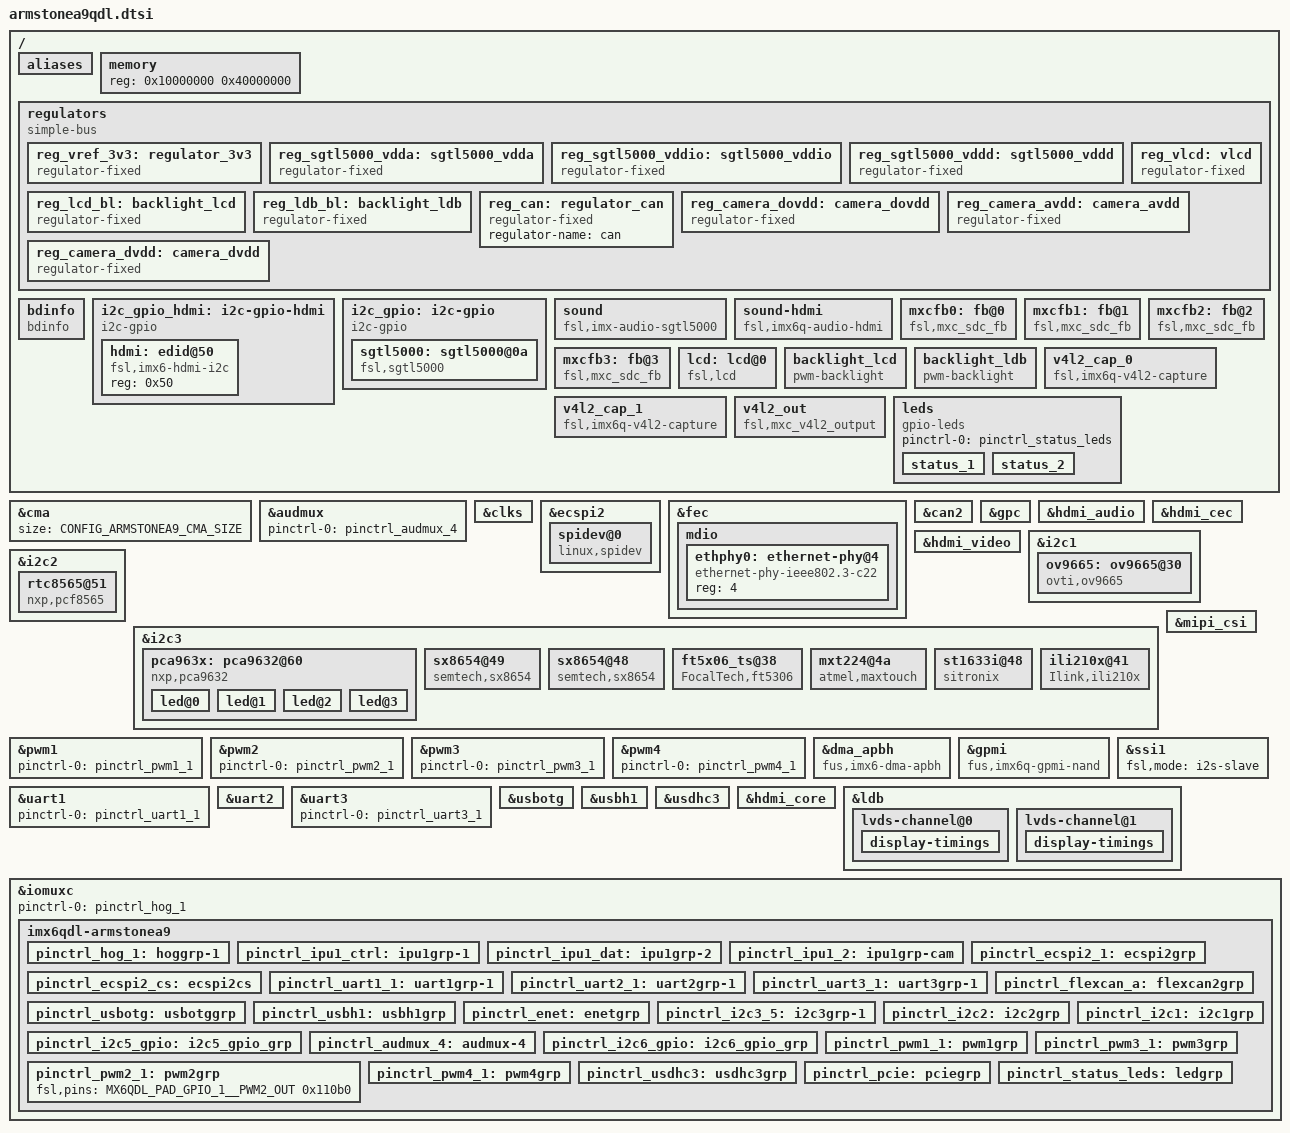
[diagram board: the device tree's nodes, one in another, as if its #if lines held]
/*
 * Copyright 2016 F&S Elektronik Systeme GmbH
 *
 * This program is free software; you can redistribute it and/or modify
 * it under the terms of the GNU General Public License version 2 as
 * published by the Free Software Foundation.
 */

#include <dt-bindings/pwm/pwm.h>

/*
 * When using one IPU, having LCD and LVDS0 at the same time is not possible,
 * because both devices would need to use display 0. But this can be simulated
 * by using LVDS1 instead of LVDS0 and activating Dual Mode.
 */
#ifdef CONFIG_ARMSTONEA9_USE_ONE_IPU
#undef CONFIG_ARMSTONEA9_MXCFB2
#undef CONFIG_ARMSTONEA9_MXCFB3

#if ((CONFIG_ARMSTONEA9_MXCFB0 == DISPLAY_LCD) \
	&& (CONFIG_ARMSTONEA9_MXCFB1 == DISPLAY_LVDS0))
#undef CONFIG_ARMSTONEA9_MXCFB1
#define CONFIG_ARMSTONEA9_MXCFB1		DISPLAY_LVDS1
#define __MOVE_LVDS0_TO_LVDS1_DUAL_MODE__
#endif

#if ((CONFIG_ARMSTONEA9_MXCFB0 == DISPLAY_LVDS0) \
	&& (CONFIG_ARMSTONEA9_MXCFB1 == DISPLAY_LCD))
#undef CONFIG_ARMSTONEA9_MXCFB0
#define CONFIG_ARMSTONEA9_MXCFB0		DISPLAY_LVDS1
#define __MOVE_LVDS0_TO_LVDS1_DUAL_MODE__
#endif

#ifdef __MOVE_LVDS0_TO_LVDS1_DUAL_MODE__
#undef CONFIG_ARMSTONEA9_LVDS1_MAPPING
#undef CONFIG_ARMSTONEA9_LVDS1_BPP
#undef CONFIG_ARMSTONEA9_LVDS1_PIX_FMT
#undef CONFIG_ARMSTONEA9_LVDS1_DATA_WIDTH
#undef CONFIG_ARMSTONEA9_LVDS1_TIMING
#define CONFIG_ARMSTONEA9_LVDS1_MAPPING		CONFIG_ARMSTONEA9_LVDS0_MAPPING
#define CONFIG_ARMSTONEA9_LVDS1_BPP		CONFIG_ARMSTONEA9_LVDS0_BPP
#define CONFIG_ARMSTONEA9_LVDS1_PIX_FMT		CONFIG_ARMSTONEA9_LVDS0_PIX_FMT
#define CONFIG_ARMSTONEA9_LVDS1_DATA_WIDTH	CONFIG_ARMSTONEA9_LVDS0_DATA_WIDTH
#define CONFIG_ARMSTONEA9_LVDS1_TIMING		CONFIG_ARMSTONEA9_LVDS0_TIMING
#ifndef CONFIG_ARMSTONEA9_LVDS_DUAL_MODE
#define CONFIG_ARMSTONEA9_LVDS_DUAL_MODE
#endif
#endif
#endif /* CONFIG_ARMSTONEA9_USE_ONE_IPU */

/* Do we have LCD? */
#if ((CONFIG_ARMSTONEA9_MXCFB0 == DISPLAY_LCD) \
    || (CONFIG_ARMSTONEA9_MXCFB1 == DISPLAY_LCD) \
    || (CONFIG_ARMSTONEA9_MXCFB2 == DISPLAY_LCD) \
    || (CONFIG_ARMSTONEA9_MXCFB3 == DISPLAY_LCD))
#define CONFIG_ARMSTONEA9_LCD
#if ((CONFIG_ARMSTONEA9_MXCFB0 == DISPLAY_LCD) \
    || (CONFIG_ARMSTONEA9_MXCFB1 == DISPLAY_LCD))
#define __LCD_ON_0_OR_1__	1
#define __LCD_ON_2_OR_3__	0
#else
#define __LCD_ON_0_OR_1__	0
#define __LCD_ON_2_OR_3__	1
#endif
#endif

/* Do we have HDMI? */
#if ((CONFIG_ARMSTONEA9_MXCFB0 == DISPLAY_HDMI) \
    || (CONFIG_ARMSTONEA9_MXCFB1 == DISPLAY_HDMI) \
    || (CONFIG_ARMSTONEA9_MXCFB2 == DISPLAY_HDMI) \
    || (CONFIG_ARMSTONEA9_MXCFB3 == DISPLAY_HDMI))
#define CONFIG_ARMSTONEA9_HDMI
#define CONFIG_ARMSTONEA9_HDMI_AUDIO
#define CONFIG_ARMSTONEA9_HDMI_CEC
#if ((CONFIG_ARMSTONEA9_MXCFB0 == DISPLAY_HDMI) \
    || (CONFIG_ARMSTONEA9_MXCFB1 == DISPLAY_HDMI))
#define __HDMI_ON_0_OR_1__	1
#define __HDMI_ON_2_OR_3__	0
#else
#define __HDMI_ON_0_OR_1__	0
#define __HDMI_ON_2_OR_3__	1
#endif
#endif

/* Do we have LVDS0? */
#if ((CONFIG_ARMSTONEA9_MXCFB0 == DISPLAY_LVDS0) \
    || (CONFIG_ARMSTONEA9_MXCFB1 == DISPLAY_LVDS0) \
    || (CONFIG_ARMSTONEA9_MXCFB2 == DISPLAY_LVDS0) \
    || (CONFIG_ARMSTONEA9_MXCFB3 == DISPLAY_LVDS0))
#define CONFIG_ARMSTONEA9_LVDS0
#if ((CONFIG_ARMSTONEA9_MXCFB0 == DISPLAY_LVDS0) \
    || (CONFIG_ARMSTONEA9_MXCFB1 == DISPLAY_LVDS0))
#define __LVDS0_ON_0_OR_1__	1
#define __LVDS0_ON_2_OR_3__	0
#else
#define __LVDS0_ON_0_OR_1__	0
#define __LVDS0_ON_2_OR_3__	1
#endif
#endif

/* Do we have LVDS1? */
#if ((CONFIG_ARMSTONEA9_MXCFB0 == DISPLAY_LVDS1) \
    || (CONFIG_ARMSTONEA9_MXCFB1 == DISPLAY_LVDS1) \
    || (CONFIG_ARMSTONEA9_MXCFB2 == DISPLAY_LVDS1) \
    || (CONFIG_ARMSTONEA9_MXCFB3 == DISPLAY_LVDS1))
#define CONFIG_ARMSTONEA9_LVDS1
#if ((CONFIG_ARMSTONEA9_MXCFB0 == DISPLAY_LVDS1) \
    || (CONFIG_ARMSTONEA9_MXCFB1 == DISPLAY_LVDS1))
#define __LVDS1_ON_0_OR_1__	1
#define __LVDS1_ON_2_OR_3__	0
#else
#define __LVDS1_ON_0_OR_1__	0
#define __LVDS1_ON_2_OR_3__	1
#endif
#endif

/* Check which LVDS will be the primary display */
#if (CONFIG_ARMSTONEA9_MXCFB0 == DISPLAY_LVDS0)
#define __LVDS0_PRIMARY__
#elif (CONFIG_ARMSTONEA9_MXCFB0 == DISPLAY_LVDS1)
#define __LVDS1_PRIMARY__
#elif (CONFIG_ARMSTONEA9_MXCFB1 == DISPLAY_LVDS0)
#define __LVDS0_PRIMARY__
#elif (CONFIG_ARMSTONEA9_MXCFB1 == DISPLAY_LVDS1)
#define __LVDS1_PRIMARY__
#elif (CONFIG_ARMSTONEA9_MXCFB2 == DISPLAY_LVDS0)
#define __LVDS0_PRIMARY__
#elif (CONFIG_ARMSTONEA9_MXCFB2 == DISPLAY_LVDS1)
#define __LVDS1_PRIMARY__
#elif (CONFIG_ARMSTONEA9_MXCFB3 == DISPLAY_LVDS0)
#define __LVDS0_PRIMARY__
#elif (CONFIG_ARMSTONEA9_MXCFB3 == DISPLAY_LVDS1)
#define __LVDS1_PRIMARY__
#endif

/ {
	aliases {
		mxcfb0 = &mxcfb0;
		mxcfb1 = &mxcfb1;
		mxcfb2 = &mxcfb2;
		mxcfb3 = &mxcfb3;
#ifdef CONFIG_ARMSTONEA9_SGTL5000_AUDIO
		i2c5 = &i2c_gpio;
#endif
#ifdef CONFIG_ARMSTONEA9_HDMI
		i2c6 = &i2c_gpio_hdmi;
#endif
	};

	memory {
		reg = <0x10000000 0x40000000>;
	};

	regulators {
		compatible = "simple-bus";

		reg_vref_3v3: regulator_3v3 {
			compatible = "regulator-fixed";
			regulator-name = "vref-3V3";
			regulator-min-microvolt = <3300000>;
			regulator-max-microvolt = <3300000>;
			regulator-always-on;
		};

		/* USB_H1_PWR/USB_OTG_PWR are always on, no regulator needed */
#if 0 //###
		reg_usb_vbus: usb_vbus {
			compatible = "regulator-fixed";
			regulator-name = "usb_vbus";
			regulator-min-microvolt = <5000000>;
			regulator-max-microvolt = <5000000>;
			/* No way to switch USB_OTG_VBUS/USB_H1_VBUS power */
			regulator-always-on;
		};
#endif //###

#ifdef CONFIG_ARMSTONEA9_SGTL5000_AUDIO
		/* SGTL5000 analog voltage */
		reg_sgtl5000_vdda: sgtl5000_vdda {
			compatible = "regulator-fixed";
			regulator-name = "VDDA-supply";
			regulator-min-microvolt = <3000000>;
			regulator-max-microvolt = <3000000>;
			regulator-always-on;
		};

		/* SGTL5000 I/O voltage */
		reg_sgtl5000_vddio: sgtl5000_vddio {
			compatible = "regulator-fixed";
			regulator-name = "VDDIO-supply";
			regulator-min-microvolt = <3300000>;
			regulator-max-microvolt = <3300000>;
			regulator-always-on;
		};

		/* SGTL5000 internal digital voltage */
		reg_sgtl5000_vddd: sgtl5000_vddd {
			compatible = "regulator-fixed";
			regulator-name = "VDDD-supply";
			regulator-min-microvolt = <1500000>;
			regulator-max-microvolt = <1500000>;
			regulator-always-on;
		};
#endif /* CONFIG_ARMSTONEA9_SGTL5000_AUDIO */

		reg_lcd_bl: backlight_lcd {
			compatible = "regulator-fixed";
			regulator-name = "lcd-bl";
			gpio = <&pca963x 0 GPIO_ACTIVE_HIGH>;
			regulator-min-microvolt = <3300000>;
			regulator-max-microvolt = <3300000>;
		};

		reg_ldb_bl: backlight_ldb {
			compatible = "regulator-fixed";
			regulator-name = "ldb-bl";
			gpio = <&gpio2 8 GPIO_ACTIVE_HIGH>;
			regulator-min-microvolt = <3300000>;
			regulator-max-microvolt = <3300000>;
			enable-active-high;
		};

		/* LCD power on voltage */
		reg_vlcd: vlcd {
			compatible = "regulator-fixed";
			regulator-name = "VLCD";
			gpio = <&gpio2 11 GPIO_ACTIVE_HIGH>;
			regulator-min-microvolt = <3300000>;
			regulator-max-microvolt = <3300000>;
		};

		/* CAN */
		reg_can: regulator_can {
			compatible = "regulator-fixed";
			regulator-name = "can";
		};

#ifdef CONFIG_ARMSTONEA9_CAMERA
		reg_camera_dovdd: camera_dovdd {
			compatible = "regulator-fixed";
			regulator-name = "DOVDD-supply";
			regulator-min-microvolt = <1800000>;
			regulator-max-microvolt = <1800000>;
		};

		reg_camera_avdd: camera_avdd {
			compatible = "regulator-fixed";
			regulator-name = "VAVDD-supply";
			regulator-min-microvolt = <2800000>;
			regulator-max-microvolt = <2800000>;
		};

		reg_camera_dvdd: camera_dvdd {
			compatible = "regulator-fixed";
			regulator-name = "DVDD-supply";
			regulator-min-microvolt = <1500000>;
			regulator-max-microvolt = <1500000>;
		};
#endif /* CONFIG_ARMSTONEA9_CAMERA */
	};

	/* F&S board information */
	bdinfo: bdinfo {
		compatible = "bdinfo";
		board_name = "armstonea9";
		ecc_strength = "8";
	};

#ifdef CONFIG_ARMSTONEA9_HDMI
	i2c_gpio_hdmi: i2c-gpio-hdmi {
		compatible = "i2c-gpio";
		gpios = <&gpio2 14 GPIO_ACTIVE_HIGH /* sda */
			 &gpio2 15 GPIO_ACTIVE_HIGH /* scl */
			>;
		pinctrl-names = "default";
		pinctrl-0 = <&pinctrl_i2c6_gpio>;
//		i2c-gpio,sda-open-drain;
//		i2c-gpio,scl-open-drain;
		i2c-gpio,delay-us = <2>;        /* ~100 kHz */
		#address-cells = <1>;
		#size-cells = <0>;
	};
#endif

#ifdef CONFIG_ARMSTONEA9_SGTL5000_AUDIO
	/* Bitbanging I2C */
	i2c_gpio: i2c-gpio {
		compatible = "i2c-gpio";
		gpios = <&gpio1 11 GPIO_ACTIVE_HIGH /* sda */
			 &gpio1 10 GPIO_ACTIVE_HIGH /* scl */
			>;
		pinctrl-names = "default";
		pinctrl-0 = <&pinctrl_i2c5_gpio>;
//		i2c-gpio,sda-open-drain;
//		i2c-gpio,scl-open-drain;
		i2c-gpio,delay-us = <2>;        /* ~100 kHz */
		#address-cells = <1>;
		#size-cells = <0>;
	};

	sound {
		compatible = "fsl,imx-audio-sgtl5000";
		cpu-dai = <&ssi1>;
		audio-codec = <&sgtl5000>;
		model = "imx-sgtl5000";
		mux-int-port = <1>;  /* SSI1=1, SSI2=2, SSI3=7 */
		mux-ext-port = <4>;
		audio-routing =
//			"MIC_IN", "Mic Jack",
			"Mic Jack", "Mic Bias",
			"LINE_IN", "Line In Jack";
//			"Line Out Jack", "LINE_OUT";
	};
#endif

#ifdef CONFIG_ARMSTONEA9_HDMI_AUDIO
	sound-hdmi {
		compatible = "fsl,imx6q-audio-hdmi",
			     "fsl,imx-audio-hdmi";
		model = "imx-audio-hdmi";
		hdmi-controller = <&hdmi_audio>;
	};
#endif

	mxcfb0: fb@0 {
		compatible = "fsl,mxc_sdc_fb";
		late_init = <0>;
#if (CONFIG_ARMSTONEA9_MXCFB0 == DISPLAY_LCD)
		disp_dev = "lcd";
		default_bpp = <CONFIG_ARMSTONEA9_LCD_BPP>;
		interface_pix_fmt = CONFIG_ARMSTONEA9_LCD_PIX_FMT;
		int_clk = <1>;
		mode_str = CONFIG_ARMSTONEA9_LCD_MODE_STR;
#elif (CONFIG_ARMSTONEA9_MXCFB0 == DISPLAY_HDMI)
		disp_dev = "hdmi";
		default_bpp = <CONFIG_ARMSTONEA9_HDMI_BPP>;
		interface_pix_fmt = CONFIG_ARMSTONEA9_HDMI_PIX_FMT;
		int_clk = <0>;
		mode_str = CONFIG_ARMSTONEA9_HDMI_MODE_STR;
#elif (CONFIG_ARMSTONEA9_MXCFB0 == DISPLAY_LVDS0)
		disp_dev = "ldb";
		default_bpp = <CONFIG_ARMSTONEA9_LVDS0_BPP>;
		interface_pix_fmt = CONFIG_ARMSTONEA9_LVDS0_PIX_FMT;
		int_clk = <1>;
#elif (CONFIG_ARMSTONEA9_MXCFB0 == DISPLAY_LVDS1)
		disp_dev = "ldb";
		default_bpp = <CONFIG_ARMSTONEA9_LVDS1_BPP>;
		interface_pix_fmt = CONFIG_ARMSTONEA9_LVDS1_PIX_FMT;
		int_clk = <1>;
#else
		status = "disabled";
#endif
	};

	mxcfb1: fb@1 {
		compatible = "fsl,mxc_sdc_fb";
		late_init = <0>;
#if (CONFIG_ARMSTONEA9_MXCFB1 == DISPLAY_LCD)
		disp_dev = "lcd";
		default_bpp = <CONFIG_ARMSTONEA9_LCD_BPP>;
		interface_pix_fmt = CONFIG_ARMSTONEA9_LCD_PIX_FMT;
		int_clk = <1>;
		mode_str = CONFIG_ARMSTONEA9_LCD_MODE_STR;
#elif (CONFIG_ARMSTONEA9_MXCFB1 == DISPLAY_HDMI)
		disp_dev = "hdmi";
		default_bpp = <CONFIG_ARMSTONEA9_HDMI_BPP>;
		interface_pix_fmt = CONFIG_ARMSTONEA9_HDMI_PIX_FMT;
		int_clk = <0>;
		mode_str = CONFIG_ARMSTONEA9_HDMI_MODE_STR;
#elif (CONFIG_ARMSTONEA9_MXCFB1 == DISPLAY_LVDS0)
		disp_dev = "ldb";
		default_bpp = <CONFIG_ARMSTONEA9_LVDS0_BPP>;
		interface_pix_fmt = CONFIG_ARMSTONEA9_LVDS0_PIX_FMT;
		int_clk = <1>;
#elif (CONFIG_ARMSTONEA9_MXCFB1 == DISPLAY_LVDS1)
		disp_dev = "ldb";
		default_bpp = <CONFIG_ARMSTONEA9_LVDS1_BPP>;
		interface_pix_fmt = CONFIG_ARMSTONEA9_LVDS1_PIX_FMT;
		int_clk = <1>;
#else
		status = "disabled";
#endif
	};

	mxcfb2: fb@2 {
		compatible = "fsl,mxc_sdc_fb";
		late_init = <0>;
#if (CONFIG_ARMSTONEA9_MXCFB2 == DISPLAY_LCD)
		disp_dev = "lcd";
		default_bpp = <CONFIG_ARMSTONEA9_LCD_BPP>;
		interface_pix_fmt = CONFIG_ARMSTONEA9_LCD_PIX_FMT;
		int_clk = <1>;
		mode_str = CONFIG_ARMSTONEA9_LCD_MODE_STR;
#elif (CONFIG_ARMSTONEA9_MXCFB2 == DISPLAY_HDMI)
		disp_dev = "hdmi";
		default_bpp = <CONFIG_ARMSTONEA9_HDMI_BPP>;
		interface_pix_fmt = CONFIG_ARMSTONEA9_HDMI_PIX_FMT;
		int_clk = <0>;
		mode_str = CONFIG_ARMSTONEA9_HDMI_MODE_STR;
#elif (CONFIG_ARMSTONEA9_MXCFB2 == DISPLAY_LVDS0)
		disp_dev = "ldb";
		default_bpp = <CONFIG_ARMSTONEA9_LVDS0_BPP>;
		interface_pix_fmt = CONFIG_ARMSTONEA9_LVDS0_PIX_FMT;
		int_clk = <1>;
#elif (CONFIG_ARMSTONEA9_MXCFB2 == DISPLAY_LVDS1)
		disp_dev = "ldb";
		default_bpp = <CONFIG_ARMSTONEA9_LVDS1_BPP>;
		interface_pix_fmt = CONFIG_ARMSTONEA9_LVDS1_PIX_FMT;
		int_clk = <1>;
#else
		status = "disabled";
#endif
	};

	mxcfb3: fb@3 {
		compatible = "fsl,mxc_sdc_fb";
		late_init = <0>;
#if (CONFIG_ARMSTONEA9_MXCFB3 == DISPLAY_LCD)
		disp_dev = "lcd";
		default_bpp = <CONFIG_ARMSTONEA9_LCD_BPP>;
		interface_pix_fmt = CONFIG_ARMSTONEA9_LCD_PIX_FMT;
		int_clk = <1>;
		mode_str = CONFIG_ARMSTONEA9_LCD_MODE_STR;
#elif (CONFIG_ARMSTONEA9_MXCFB3 == DISPLAY_HDMI)
		disp_dev = "hdmi";
		default_bpp = <CONFIG_ARMSTONEA9_HDMI_BPP>;
		interface_pix_fmt = CONFIG_ARMSTONEA9_HDMI_PIX_FMT;
		int_clk = <0>;
		mode_str = CONFIG_ARMSTONEA9_HDMI_MODE_STR;
#elif (CONFIG_ARMSTONEA9_MXCFB3 == DISPLAY_LVDS0)
		disp_dev = "ldb";
		default_bpp = <CONFIG_ARMSTONEA9_LVDS0_BPP>;
		interface_pix_fmt = CONFIG_ARMSTONEA9_LVDS0_PIX_FMT;
		int_clk = <1>;
#elif (CONFIG_ARMSTONEA9_MXCFB3 == DISPLAY_LVDS1)
		disp_dev = "ldb";
		default_bpp = <CONFIG_ARMSTONEA9_LVDS1_BPP>;
		interface_pix_fmt = CONFIG_ARMSTONEA9_LVDS1_PIX_FMT;
		int_clk = <1>;
#else
		status = "disabled";
#endif
	};

	lcd: lcd@0 {
		compatible = "fsl,lcd";
		power-supply = <&reg_vlcd>;
		pinctrl-names = "default";
		pinctrl-0 = <&pinctrl_ipu1_ctrl &pinctrl_ipu1_dat>;
		status = "disabled";
	};

	/* RGB-LCD backlight PWM on RGB adapter */
	backlight_lcd {
		compatible = "pwm-backlight";
		pwms = <&pca963x 1 640000 PWM_POLARITY_INVERTED>;
		power-supply = <&reg_lcd_bl>;
		brightness-levels = <0 1 5 10 18 28 41 56
				     73 92 113 137 163 192 222 255>;
		default-brightness-level = <14>;
		fb-names = "mxs-lcdif1";
	};

	/* LVDS backlight PWM on LVDS connector and backlight connector */
	backlight_ldb {
		compatible = "pwm-backlight";
		pwms = <&pwm3 0 5000000>;
		power-supply = <&reg_ldb_bl>;
		brightness-levels = <0 1 5 10 18 28 41 56
				     73 92 113 137 163 192 222 255>;
		default-brightness-level = <14>;
		fb-names = "mxs-lcdif2";
	};

#ifdef CONFIG_ARMSTONEA9_CAMERA
#ifdef CONFIG_ARMSTONEA9_PARALLEL_CAMERA
	/* Parallel digital camera interface */
	v4l2_cap_0 {
		compatible = "fsl,imx6q-v4l2-capture";
		ipu_id = <0>;
		csi_id = <0>;
		mclk_source = <0>;
		status = "okay";
	};
#endif

#ifdef CONFIG_ARMSTONEA9_SERIAL_CAMERA
	/* Serial MIPI camera interface */
	v4l2_cap_1 {
		compatible = "fsl,imx6q-v4l2-capture";
		ipu_id = <0>;
		csi_id = <1>;
		mclk_source = <0>;
		status = "okay";
	};
#endif

	v4l2_out {
		compatible = "fsl,mxc_v4l2_output";
		status = "okay";
	};
#endif

	leds {
		compatible = "gpio-leds";
		pinctrl-names = "default";
		pinctrl-0 = <&pinctrl_status_leds>;

		status_1 {
			label = "Status1";
			gpios = <&gpio4 6 GPIO_ACTIVE_HIGH>;
			default-state = "keep";
		};

		status_2 {
			label = "Status2";
			gpios = <&gpio4 7 GPIO_ACTIVE_HIGH>;
			default-state = "keep";
		};
	};
};

/* RAM size for Continues Memory Allocator; if not defined, use 320 MB */
#ifndef CONFIG_ARMSTONEA9_CMA_SIZE
#define CONFIG_ARMSTONEA9_CMA_SIZE 0x14000000
#endif
&cma {
	size = <CONFIG_ARMSTONEA9_CMA_SIZE>;
};

#if defined(CONFIG_ARMSTONEA9_SGTL5000_AUDIO) || \
	defined(CONFIG_ARMSTONEA9_HDMI_AUDIO)
&audmux {
	pinctrl-names = "default";
	pinctrl-0 = <&pinctrl_audmux_4>;
	status = "okay";
};
#endif

/* if you want to use the pmic controller you have to set the arm-supply and
 * the soc-supply to the regulator of the pmic. Look pfuze comment.*/
#if 0
&cpu0 {
	arm-supply = <&sw1a_reg>;
	soc-supply = <&sw1c_reg>;
};
#endif

&clks {
	assigned-clocks = <&clks IMX6QDL_CLK_PLL4_AUDIO_DIV>,
			  <&clks IMX6QDL_CLK_SSI1_SEL>,
			  <&clks IMX6QDL_CLK_SSI1>,
			  <&clks IMX6QDL_CLK_CKO2_SEL>,
			  <&clks IMX6QDL_CLK_CKO>;

	assigned-clock-parents = <0>,
				 <&clks IMX6QDL_CLK_PLL4_AUDIO_DIV>,
				 <0>,
				 <&clks IMX6QDL_CLK_SSI1>,
				 <&clks IMX6QDL_CLK_CKO2>;
//###	assigned-clock-rates = <786432000>, <0>, <24576000>;
	assigned-clock-rates = <786432000>, <0>, <12288000>;
};

#ifdef CONFIG_ARMSTONEA9_SPI_A
/* SPI_A (2x CS) */
&ecspi2 {
	fsl,spi-num-chipselects = <2>;
	cs-gpios = <&gpio2 26 GPIO_ACTIVE_HIGH>; /* SPI_A_CS1 */
	pinctrl-names = "default";
	pinctrl-0 = <&pinctrl_ecspi2_1 &pinctrl_ecspi2_cs>;
	status = "okay";

	spidev@0 {
		#address-cells = <1>;
		#size-cells = <1>;
		compatible = "linux,spidev";
		spi-max-frequency = <20000000>;
		reg = <0>;
	};
};
#endif /* CONFIG_ARMSTONEA9_SPI_A */

&fec {
	pinctrl-names = "default";
	pinctrl-0 = <&pinctrl_enet>;
	phy-mode = "rgmii";
	phy-handle = <&ethphy0>;
	phy-supply = <&reg_vref_3v3>;
	status = "okay";

	mdio {
		#address-cells = <1>;
		#size-cells = <0>;

		ethphy0: ethernet-phy@4 {
			compatible = "ethernet-phy-ieee802.3-c22";
			reg = <4>;
			/* Set the maximum link speed if required */
			//max-speed = <100>;
		};
	};
};

/* CANRX1 Pin 63 & CANTX1 Pin 64 */
&can2 {
	pinctrl-names = "default";
	pinctrl-0 = <&pinctrl_flexcan_a>;
	xceiver-supply = <&reg_can>;
	status = "okay";
};

&gpc {
	fsl,cpu_pupscr_sw2iso = <0xf>;
	fsl,cpu_pupscr_sw = <0xf>;
	fsl,cpu_pdnscr_iso2sw = <0x1>;
	fsl,cpu_pdnscr_iso = <0x1>;
	/* more information how to ldo-bypass look at pfuze comment in i2c2 */
	fsl,ldo-bypass = <0>; /* use ldo-bypass, u-boot will check it and configure */
	fsl,wdog-reset = <1>; /* watchdog select of reset source */
};

#ifdef CONFIG_ARMSTONEA9_HDMI_AUDIO
&hdmi_audio {
	status = "okay";
};
#endif

#ifdef CONFIG_ARMSTONEA9_HDMI_CEC
&hdmi_cec {
//###	pinctrl-names = "default";
//###	pinctrl-0 = <&pinctrl_hdmi_cec_1>;
	status = "okay";
};
#endif

#ifdef CONFIG_ARMSTONEA9_HDMI
&hdmi_video {
	fsl,phy_reg_vlev = <0x0294>;
	fsl,phy_reg_cksymtx = <0x800d>;
	status = "okay";
};
#endif

#ifdef CONFIG_ARMSTONEA9_I2C_C
/* Additional I2C bus on feature connector pins 18, 26 */
&i2c1 {
	clock-frequency = <200000>;
	pinctrl-names = "default";
	pinctrl-0 = <&pinctrl_i2c1>;
	status = "okay";

#if 0
#ifdef CONFIG_ARMSTONEA9_SERIAL_CAMERA
	ov564x_mipi: ov564x_mipi@3c {
		compatible = "ovti,ov564x_mipi";
		reg = <0x3c>;
		/* derived from IMX6QDL_CLK_CKO2 */
		clocks = <&clks IMX6QDL_CLK_CKO>;
		clock-names = "csi_mclk";
		DOVDD-supply = <&reg_camera_dovdd>; /* 1.8v */
		AVDD-supply = <&reg_camera_avdd>;  /* 2.8v, rev C board is VGEN3
						rev B board is VGEN5 */
		DVDD-supply = <&reg_camera_dvdd>;  /* 1.5v*/
		pwn-gpios = <&gpio5 24 GPIO_ACTIVE_HIGH>;
		/* not available */
		rst-gpios = <&gpio5 23 GPIO_ACTIVE_LOW>;
		csi_id = <1>;
		mclk = <24000000>;
		mclk_source = <0>;
	};
#endif /* CONFIG_ARMSTONEA9_SERIAL_CAMERA */
#endif

#ifdef CONFIG_ARMSTONEA9_PARALLEL_CAMERA
	ov9665: ov9665@30 {
		compatible = "ovti,ov9665";
		reg = <0x30>;
		pinctrl-names = "default";
		pinctrl-0 = <&pinctrl_ipu1_2>;
		clocks = <&clks IMX6QDL_CLK_CKO>;
		clock-names = "csi_mclk";
		DOVDD-supply = <&reg_camera_dovdd>; /* 1.8v */
		AVDD-supply = <&reg_camera_avdd>;  /* 2.8v, rev C board is VGEN3
						rev B board is VGEN5 */
		DVDD-supply = <&reg_camera_dvdd>;  /* 1.5v*/
		pwn-gpios = <&gpio5 24 GPIO_ACTIVE_HIGH>;
		rst-gpios = <&gpio5 23 GPIO_ACTIVE_LOW>;
		csi_id = <0>;
		mclk = <24000000>;
		mclk_source = <0>;
	};
#endif /* CONFIG_ARMSTONEA9_PARALLEL_CAMERA */
};
#endif /* CONFIG_ARMSTONEA9_I2C_C */

#ifdef CONFIG_ARMSTONEA9_I2C_B
&i2c2 {
	clock-frequency = <200000>;
	pinctrl-names = "default";
	pinctrl-0 = <&pinctrl_i2c2>;
	status = "okay";

	rtc8565@51 {
		compatible = "nxp,pcf8565", "nxp,pcf8563";
		reg = <0x51>;
		interrupt-parent = <&gpio1>;
		interrupts = <28 IRQ_TYPE_EDGE_FALLING>;
	};

	// ### TODO: ADC

/* if you want to use pmic you have to set these regulators. But the pmic
 * control register will be set by the UBoot so if you want use it you have to
 * implement that the pmu_reg_core register will be set to "Power FET switched
 * full on", because this set the bypass, so the pmic controlls the CPU.
 */
#if 0
	pmic: pfuze100@08 {
		compatible = "fsl,pfuze100";
		reg = <0x08>;

		regulators {
			sw1a_reg: sw1ab {
				regulator-min-microvolt = <300000>;
				regulator-max-microvolt = <1875000>;
				regulator-boot-on;
				regulator-always-on;
				regulator-ramp-delay = <6250>;
			};

			sw1c_reg: sw1c {
				regulator-min-microvolt = <300000>;
				regulator-max-microvolt = <1875000>;
				regulator-boot-on;
				regulator-always-on;
				regulator-ramp-delay = <6250>;
			};

			sw2_reg: sw2 {
				//regulator-min-microvolt = <800000>;
				regulator-min-microvolt = <400000>;
				regulator-max-microvolt = <3300000>;
				regulator-boot-on;
				regulator-always-on;
				regulator-ramp-delay = <6250>;
			};

			sw3a_reg: sw3a {
				regulator-min-microvolt = <400000>;
				//regulator-max-microvolt = <1975000>;
				regulator-max-microvolt = <3300000>;
				regulator-boot-on;
				regulator-always-on;
			};

			sw3b_reg: sw3b {
				regulator-min-microvolt = <400000>;
				//regulator-max-microvolt = <1975000>;
				regulator-max-microvolt = <3300000>;
				regulator-boot-on;
				regulator-always-on;
			};

			sw4_reg: sw4 {
				//regulator-min-microvolt = <800000>;
				regulator-min-microvolt = <400000>;
				regulator-max-microvolt = <3300000>;
			};

			swbst_reg: swbst {
				regulator-min-microvolt = <5000000>;
				regulator-max-microvolt = <5150000>;
			};

			snvs_reg: vsnvs {
				regulator-min-microvolt = <1000000>;
				regulator-max-microvolt = <3000000>;
				regulator-boot-on;
				regulator-always-on;
			};

			vref_reg: vrefddr {
				regulator-boot-on;
				regulator-always-on;
			};

			vgen1_reg: vgen1 {
				regulator-min-microvolt = <800000>;
				regulator-max-microvolt = <1550000>;
			};

			vgen2_reg: vgen2 {
				regulator-min-microvolt = <800000>;
				regulator-max-microvolt = <1550000>;
			};

			vgen3_reg: vgen3 {
				regulator-min-microvolt = <1800000>;
				regulator-max-microvolt = <3300000>;
			};

			vgen4_reg: vgen4 {
				regulator-min-microvolt = <1800000>;
				regulator-max-microvolt = <3300000>;
				regulator-always-on;
			};

			vgen5_reg: vgen5 {
				regulator-min-microvolt = <1800000>;
				regulator-max-microvolt = <3300000>;
				regulator-always-on;
			};

			vgen6_reg: vgen6 {
				regulator-min-microvolt = <1800000>;
				regulator-max-microvolt = <3300000>;
				regulator-always-on;
			};
		};
	};
#endif
};
#endif /* CONFIG_ARMSTONEA9_I2C_B */

#ifdef CONFIG_ARMSTONEA9_I2C_A
&i2c3 {
	clock-frequency = <100000>;
	pinctrl-names = "default";
	pinctrl-0 = <&pinctrl_i2c3_5>;
	status = "okay";

	pca963x: pca9632@60 {
		compatible = "nxp,pca9632";
		reg = <0x60>;
		nxp,totem-pole;
		#address-cells = <1>;
		#size-cells = <0>;
		#pwm-cells = <3>;
		#gpio-cells = <2>;
		led@0 {
			reg = <0>;
			label = "0-PWRCTL";
			type = "GPIO";
			default-on;
			active-high;
		};
		led@1 {
			reg = <1>;
			label = "1-LEDCTRL";
			type = "PWM";
			default-on;
		};
		led@2 {
			reg = <2>;
			label = "2-ROTATE";
			type = "GPIO";
			active-high;
		};
		led@3 {
			reg = <3>;
			label = "3-unused";
			type = "LED";
		};
	};

#ifdef CONFIG_ARMSTONEA9_4WTOUCH_SX8655_RGBADAPTER
	/* 4/5 wire analog resistive touch, on RGB LCD adapter */
	sx8654@49 {
		compatible = "semtech,sx8654";
		reg = <0x49>;
		touchrate = <0x30>;
		powdly = <0x06>;
		filt = <0x02>;
		setdly = <0x08>;
		pinctrl-names = "default";
		interrupt-parent = <&gpio1>;
		interrupts = <30 IRQ_TYPE_EDGE_FALLING>;
		reset-gpio = <&gpio1 29 GPIO_ACTIVE_LOW>;
	};
#endif

#ifdef CONFIG_ARMSTONEA9_4WTOUCH_SX8655
	/* 4/5 wire analog resistive touch on Touch Connector (I2C) */
	sx8654@48 {
		compatible = "semtech,sx8654";
		reg = <0x48>;
		touchrate = <0x30>;
		powdly = <0x06>;
		filt = <0x02>;
		setdly = <0x08>;
		pinctrl-names = "default";
		interrupt-parent = <&gpio1>;
		interrupts = <30 IRQ_TYPE_EDGE_FALLING>;
		reset-gpio = <&gpio1 29 GPIO_ACTIVE_LOW>;
	};
#endif

#ifdef CONFIG_ARMSTONEA9_CAPTOUCH_FT5x06
	/* F&S driver V3.0 on Touch Connector (I2C) */
	ft5x06_ts@38 {
		compatible = "FocalTech,ft5306";
		reg = <0x38>;
		fingers = <2>;
		touchscreen-size-x = <800>;
		touchscreen-size-y = <480>;
		threshold = <25>;
		interrupt-parent = <&gpio1>;
		interrupts = <30 IRQ_TYPE_EDGE_FALLING>;
		reset-gpios = <&gpio1 29 GPIO_ACTIVE_LOW>;
		linux,wakeup;
	};
#endif

#ifdef CONFIG_ARMSTONEA9_CAPTOUCH_MXT224
	/* Atmel PCAP touch on Touch Connector (I2C) */
	mxt224@4a {
		compatible = "atmel,maxtouch";
		reg = <0x4a>;
		interrupt-parent = <&gpio1>;
		interrupts = <30 IRQ_TYPE_EDGE_FALLING>;
		atmel,cfg_name = "atmel/mxt224.cfg";
		atmel,reset-gpio = <&gpio1 29 GPIO_ACTIVE_LOW>;
	};
#endif

#ifdef CONFIG_ARMSTONEA9_CAPTOUCH_SITRONIX
	/* Sitronix PCAP touch on Touch-Connector (I2C) */
	st1633i@48 {
		compatible = "sitronix";
		reg = <0x48>;
		swap-xy;
		interrupt-parent = <&gpio1>;
		interrupts = <30 IRQ_TYPE_EDGE_FALLING>;
		reset-gpio = <&gpio1 29 GPIO_ACTIVE_LOW>;
	};
#endif

#ifdef CONFIG_ARMSTONEA9_CAPTOUCH_ILINK
	/* Ilink PCAP touch on Touch-Connector (I2C) */
	ili210x@41 {
		compatible = "Ilink,ili210x";
		reg = <0x41>;
		interrupt-parent = <&gpio1>;
		interrupts = <30 IRQ_TYPE_EDGE_FALLING>;
		reset-gpio = <&gpio1 29 GPIO_ACTIVE_LOW>;
	};
#endif
};
#endif /* CONFIG_ARMSTONEA9_I2C_A */

#ifdef CONFIG_ARMSTONEA9_SGTL5000_AUDIO
/* I2C_C (Bitbanging): RTC (PCA8565), SGTL5000 (SKIT) */
&i2c_gpio {
		sgtl5000: sgtl5000@0a {
			compatible = "fsl,sgtl5000";
			reg = <0x0a>;
			mono2both;
			clocks = <&clks IMX6QDL_CLK_CKO>;
			VDDA-supply = <&reg_sgtl5000_vdda>;
			VDDIO-supply = <&reg_sgtl5000_vddio>;
			VDDD-supply = <&reg_sgtl5000_vddd>;
		};
};
#endif /* CONFIG_ARMSTONEA9_SGTL5000_AUDIO */

#ifdef CONFIG_ARMSTONEA9_HDMI
&i2c_gpio_hdmi {
	hdmi: edid@50 {
		compatible = "fsl,imx6-hdmi-i2c";
		reg = <0x50>;
	};
};
#endif

/* PWM_C (Feature connector pin 32) */
&pwm1 {
	pinctrl-names = "default";
	pinctrl-0 = <&pinctrl_pwm1_1>;
	status = "okay";
};

/* PWM_A (Feature connector pin 28) */
&pwm2 {
	pinctrl-names = "default";
	pinctrl-0 = <&pinctrl_pwm2_1>;
	status = "okay";
};

/* Backlight PWM (Connector X8 Pin 25 & X9 Pin 3) */
&pwm3 {
	pinctrl-names = "default";
	pinctrl-0 = <&pinctrl_pwm3_1>;
	status = "okay";
};

/* PWM_B (Feature connector pin 30) */
&pwm4 {
	pinctrl-names = "default";
	pinctrl-0 = <&pinctrl_pwm4_1>;
	status = "okay";
};

&dma_apbh {
	/* Switch to F&S implementation of APBH DMA driver for GPMI (NAND) */
	compatible = "fus,imx6-dma-apbh", "fus,imx28-dma-apbh";
};

#ifdef CONFIG_ARMSTONEA9_NAND
&gpmi {
	/* Switch to F&S implementation of GPMI NAND driver */
	compatible = "fus,imx6q-gpmi-nand";
	pinctrl-names = "default";
//###	pinctrl-0 = <&pinctrl_gpmi_nand_1>;
	fus,skipblocks = <2>;
	fus,chunk1k;
	fus,ecc_strength = <8>;		/* Spare area 64 bytes */
	//fus,ecc_strength = <40>;	/* Spare area 224 bytes */
	status = "okay";
};
#endif

#ifdef CONFIG_ARMSTONEA9_SERIAL_CAMERA
&mipi_csi {
	status = "okay";
	ipu_id = <0>;
	csi_id = <1>;
	v_channel = <0>;
	lanes = <2>;
};
#endif

#ifdef CONFIG_ARMSTONEA9_SGTL5000_AUDIO
&ssi1 {
	fsl,mode = "i2s-slave";
	status = "okay";
};
#endif /* CONFIG_ARMSTONEA9_SGTL5000_AUDIO */

#ifdef CONFIG_ARMSTONEA9_UART_B
/* UART1 on pins 13, 15 (port B)*/
&uart1 {
	pinctrl-names = "default";
	pinctrl-0 = <&pinctrl_uart1_1>;
	status = "okay";
};
#endif /* CONFIG_ARMSTONEA9_UART_B */

#ifdef CONFIG_ARMSTONEA9_UART_A
/* UART2 on pins 55-58 (debug port A)*/
&uart2 {
	pinctrl-names = "default";
	pinctrl-0 = <&pinctrl_uart2_1>;
	fsl,uart-has-rtscts;
	status = "okay";
};
#endif /* CONFIG_ARMSTONEA9_UART_A */

#ifdef CONFIG_ARMSTONEA9_UART_C
/* UART3 on pins 36, 38 (port C) */
&uart3 {
	pinctrl-names = "default";
	pinctrl-0 = <&pinctrl_uart3_1>;
	status = "okay";
};
#endif /* CONFIG_ARMSTONEA9_UART_C */

&usbotg {
	pinctrl-names = "default";
	pinctrl-0 = <&pinctrl_usbotg>;
//###	vbus-supply = <&reg_usb_vbus>;
	disable-over-current;
	status = "okay";
};

&usbh1 {
	pinctrl-names = "default";
	pinctrl-0 = <&pinctrl_usbh1>;
//###	vbus-supply = <&reg_usb_vbus>;
	disable-over-current;
	status = "okay";
};

#ifdef CONFIG_ARMSTONEA9_SD_A
&usdhc3 {
	/* Micro-SD-Card-Slot, CD is active low */
	pinctrl-names = "default";
	pinctrl-0 = <&pinctrl_usdhc3>;
	cd-gpios = <&gpio6 15 GPIO_ACTIVE_LOW>;
	status = "okay";
};
#endif /* CONFIG_ARMSTONEA9_SD_A */

#ifdef CONFIG_ARMSTONEA9_LCD
&lcd {
	/* LCD on armStoneA9 is always on IPU1 (id=0), DI0 */
	ipu_id = <0>;
	disp_id = <0>;
	default_ifmt = CONFIG_ARMSTONEA9_LCD_PIX_FMT;
	status = "okay";
};
#endif

#ifdef CONFIG_ARMSTONEA9_HDMI
&hdmi_core {
#ifdef CONFIG_ARMSTONEA9_USE_ONE_IPU
	/*
	 * When using one IPU (id=0):
	 * HDMI can go to DI1, unless LVDS1 is also active. In this case LVDS1
	 * must go to DI1 and HDMI to DI0.
	 */
	ipu_id = <0>;
#if (__HDMI_ON_0_OR_1__ && __LVDS1_ON_0_OR_1__)
	disp_id = <0>;
#else
	disp_id = <1>;
#endif
#else /* !CONFIG_ARMSTONEA9_USE_ONE_IPU */
	/*
	 * When using two IPUs:
 	 * HDMI can always go to DI1. If HDMI is on MXCFB0 and LCD on MXCFB1,
	 * or vice versa, or HDMI is on MXCFB2 and LCD is on MXCFB3, or vice
	 * versa, then HDMI has to go to IPU2 (id=1), otherwise to IPU1 (id=0).
	 */
	disp_id = <1>;
#if ((__HDMI_ON_0_OR_1__ && __LCD_ON_0_OR_1__) \
    || (__HDMI_ON_2_OR_3__ && __LCD_ON_2_OR_3__))
	ipu_id = <1>;
#else
	ipu_id = <0>;
#endif
#endif /* CONFIG_ARMSTONEA9_USE_ONE_IPU */
	status = "okay";
};
#endif

#if (defined(CONFIG_ARMSTONEA9_LVDS0) || defined(CONFIG_ARMSTONEA9_LVDS1))
&ldb {
	ext_ref;
#if defined(CONFIG_ARMSTONEA9_LVDS_SPLIT_MODE)
	split-mode;
#elif defined(CONFIG_ARMSTONEA9_LVDS_DUAL_MODE)
	dual-mode;
#endif
	power-supply = <&reg_vlcd>;
	status = "okay";

#ifdef CONFIG_ARMSTONEA9_LVDS0
	/* LVDS0 must always go to DI0 of an IPU! */
	lvds-channel@0 {
		reg = <0>;
#ifdef CONFIG_ARMSTONEA9_USE_ONE_IPU
		crtc = "ipu1-di0";
#else
		crtc = "ipu2-di0";
#endif
		fsl,data-mapping = CONFIG_ARMSTONEA9_LVDS0_MAPPING;
		fsl,data-width = <CONFIG_ARMSTONEA9_LVDS0_DATA_WIDTH>;
#ifdef __LVDS0_PRIMARY__
		primary;
#endif
		status = "okay";

		display-timings {
			native-mode = <&timing0>;
			timing0: CONFIG_ARMSTONEA9_LVDS0_TIMING;
		};
	};
#endif

#ifdef CONFIG_ARMSTONEA9_LVDS1
	/* LVDS1 must always go to DI1 of an IPU! */
	lvds-channel@1 {
#if defined(CONFIG_ARMSTONEA9_LVDS_DUAL_MODE) \
	|| defined(CONFIG_ARMSTONEA9_LVDS_SPLIT_MODE)
		reg = <0>;
#else
		reg = <1>;
#endif
#if (defined(CONFIG_ARMSTONEA9_USE_ONE_IPU) \
    || (__LVDS0_ON_0_OR_1__ && __LVDS1_ON_0_OR_1__) \
    || (__LVDS0_ON_2_OR_3__ && __LVDS1_ON_2_OR_3__))
		crtc = "ipu1-di1";
#else
		crtc = "ipu2-di1";
#endif
		fsl,data-mapping = CONFIG_ARMSTONEA9_LVDS1_MAPPING;
		fsl,data-width = <CONFIG_ARMSTONEA9_LVDS1_DATA_WIDTH>;
#ifdef __LVDS1_PRIMARY__
		primary;
#endif
		status = "okay";

		display-timings {
			native-mode = <&timing1>;
			timing1: CONFIG_ARMSTONEA9_LVDS1_TIMING;
		};
	};
#endif
};
#endif /* CONFIG_ARMSTONEA9_LVDS0 || CONFIG_ARMSTONEA9_LVDS1 */

#if 0 // not tested
&pcie {
	pinctrl-names = "default";
	pinctrl-0 = <&pinctrl_pcie>;
	disable-gpio = <&gpio5 15 GPIO_ACTIVE_LOW>;
	power-on-gpio = <&gpio6 16 GPIO_ACTIVE_LOW>;
	reset-gpio = <&gpio5 17 GPIO_ACTIVE_LOW>;
	status = "okay";
};
#endif

&iomuxc {
	pinctrl-names = "default";
	pinctrl-0 = <&pinctrl_hog_1>;

	imx6qdl-armstonea9 {
		/* Pin configs that don't belong anywhere else */
		pinctrl_hog_1: hoggrp-1 {
			fsl,pins = <
				/* Audio clock 24MHz */
				MX6QDL_PAD_GPIO_0__CCM_CLKO1		0x130b0

				/* VLCD_ON for reg_vlcd */
				MX6QDL_PAD_SD4_DAT3__GPIO2_IO11		0x13059

				/* VBL_ON for backlight on */
				MX6QDL_PAD_SD4_DAT0__GPIO2_IO08		0x13059

				/* WDOG1, value from NBoot */
				MX6QDL_PAD_GPIO_9__WDOG1_B		0x8

				/* I2C2_IRQn (SX8655, ext. touch) */
				MX6QDL_PAD_ENET_TXD0__GPIO1_IO30	0xb0b0

				/* camera powerdown - active high */
				MX6QDL_PAD_CSI0_DAT6__GPIO5_IO24	0x17059

				/* camera reset - active low */
				MX6QDL_PAD_CSI0_DAT5__GPIO5_IO23	0x17059

				/* RTC_IRQ */
				MX6QDL_PAD_ENET_TX_EN__GPIO1_IO28	0xb0b0
			>;
		};

#if 0
		/* Pins already set in bootloader */
		pinctrl_gpmi_nand_1: gpmi-nand-1 {
			fsl,pins = <
				MX6QDL_PAD_NANDF_CLE__NAND_CLE		0xb0b1
				MX6QDL_PAD_NANDF_ALE__NAND_ALE		0xb0b1
				MX6QDL_PAD_NANDF_WP_B__NAND_WP_B	0xb0b1
				MX6QDL_PAD_NANDF_RB0__NAND_READY_B	0xb000
				MX6QDL_PAD_NANDF_CS0__NAND_CE0_B	0xb0b1
				MX6QDL_PAD_SD4_CMD__NAND_RE_B		0xb0b1
				MX6QDL_PAD_SD4_CLK__NAND_WE_B		0xb0b1
				MX6QDL_PAD_NANDF_D0__NAND_DATA00	0xb0b1
				MX6QDL_PAD_NANDF_D1__NAND_DATA01	0xb0b1
				MX6QDL_PAD_NANDF_D2__NAND_DATA02	0xb0b1
				MX6QDL_PAD_NANDF_D3__NAND_DATA03	0xb0b1
				MX6QDL_PAD_NANDF_D4__NAND_DATA04	0xb0b1
				MX6QDL_PAD_NANDF_D5__NAND_DATA05	0xb0b1
				MX6QDL_PAD_NANDF_D6__NAND_DATA06	0xb0b1
				MX6QDL_PAD_NANDF_D7__NAND_DATA07	0xb0b1
			>;
		};
#endif

		/* LCD interface */
		pinctrl_ipu1_ctrl: ipu1grp-1 {
			fsl,pins = <
				MX6QDL_PAD_DI0_DISP_CLK__IPU1_DI0_DISP_CLK 0x10
				MX6QDL_PAD_DI0_PIN2__IPU1_DI0_PIN02	   0x10
				MX6QDL_PAD_DI0_PIN3__IPU1_DI0_PIN03	   0x10
				MX6QDL_PAD_DI0_PIN15__IPU1_DI0_PIN15	   0x10
			>;
		};

		pinctrl_ipu1_dat: ipu1grp-2 {
			fsl,pins = <
			/* LCD interface */
				MX6QDL_PAD_DISP0_DAT0__IPU1_DISP0_DATA00   0x10
				MX6QDL_PAD_DISP0_DAT1__IPU1_DISP0_DATA01   0x10
				MX6QDL_PAD_DISP0_DAT2__IPU1_DISP0_DATA02   0x10
				MX6QDL_PAD_DISP0_DAT3__IPU1_DISP0_DATA03   0x10
				MX6QDL_PAD_DISP0_DAT4__IPU1_DISP0_DATA04   0x10
				MX6QDL_PAD_DISP0_DAT5__IPU1_DISP0_DATA05   0x10
				MX6QDL_PAD_DISP0_DAT6__IPU1_DISP0_DATA06   0x10
				MX6QDL_PAD_DISP0_DAT7__IPU1_DISP0_DATA07   0x10
				MX6QDL_PAD_DISP0_DAT8__IPU1_DISP0_DATA08   0x10
				MX6QDL_PAD_DISP0_DAT9__IPU1_DISP0_DATA09   0x10
				MX6QDL_PAD_DISP0_DAT10__IPU1_DISP0_DATA10  0x10
				MX6QDL_PAD_DISP0_DAT11__IPU1_DISP0_DATA11  0x10
				MX6QDL_PAD_DISP0_DAT12__IPU1_DISP0_DATA12  0x10
				MX6QDL_PAD_DISP0_DAT13__IPU1_DISP0_DATA13  0x10
				MX6QDL_PAD_DISP0_DAT14__IPU1_DISP0_DATA14  0x10
				MX6QDL_PAD_DISP0_DAT15__IPU1_DISP0_DATA15  0x10
				MX6QDL_PAD_DISP0_DAT16__IPU1_DISP0_DATA16  0x10
				MX6QDL_PAD_DISP0_DAT17__IPU1_DISP0_DATA17  0x10
			>;
		};

#ifdef CONFIG_ARMSTONEA9_PARALLEL_CAMERA
		pinctrl_ipu1_2: ipu1grp-cam { /* parallel camera */
			fsl,pins = <
				MX6QDL_PAD_CSI0_DAT10__IPU1_CSI0_DATA10	0x1b0b0
				MX6QDL_PAD_CSI0_DAT11__IPU1_CSI0_DATA11	0x1b0b0
				MX6QDL_PAD_CSI0_DAT12__IPU1_CSI0_DATA12	0x1b0b0
				MX6QDL_PAD_CSI0_DAT13__IPU1_CSI0_DATA13	0x1b0b0
				MX6QDL_PAD_CSI0_DAT14__IPU1_CSI0_DATA14	0x1b0b0
				MX6QDL_PAD_CSI0_DAT15__IPU1_CSI0_DATA15	0x1b0b0
				MX6QDL_PAD_CSI0_DAT16__IPU1_CSI0_DATA16	0x1b0b0
				MX6QDL_PAD_CSI0_DAT17__IPU1_CSI0_DATA17	0x1b0b0
				MX6QDL_PAD_CSI0_DAT18__IPU1_CSI0_DATA18	0x1b0b0
				MX6QDL_PAD_CSI0_DAT19__IPU1_CSI0_DATA19	0x1b0b0
				MX6QDL_PAD_CSI0_PIXCLK__IPU1_CSI0_PIXCLK 0x1b0b0
				MX6QDL_PAD_CSI0_MCLK__IPU1_CSI0_HSYNC	0x1b0b0
				MX6QDL_PAD_CSI0_VSYNC__IPU1_CSI0_VSYNC	0x1b0b0
			>;
		};
#endif /* CONFIG_ARMSTONEA9_PARALLEL_CAMERA */

#ifdef CONFIG_ARMSTONEA9_SPI_A
		/* ECSPI2 - SPI_A */
		pinctrl_ecspi2_1: ecspi2grp {
			fsl,pins = <
				MX6QDL_PAD_EIM_OE__ECSPI2_MISO		0x100b1
				MX6QDL_PAD_EIM_CS1__ECSPI2_MOSI		0x100b1
				MX6QDL_PAD_EIM_CS0__ECSPI2_SCLK		0x100b1
			>;
		};
		pinctrl_ecspi2_cs: ecspi2cs {
			fsl,pins = <
				/* ECSPI2_SS0 - slave (chip) select 0 */
				MX6QDL_PAD_EIM_RW__GPIO2_IO26		0x1b0b0
			>;
		};
#endif /* CONFIG_ARMSTONEA9_SPI_A */

#ifdef CONFIG_ARMSTONEA9_UART_B
		/* UART1 on pins 13, 15 (port B)*/
		pinctrl_uart1_1: uart1grp-1{
			fsl,pins = <
				MX6QDL_PAD_CSI0_DAT10__UART1_TX_DATA	0x1b0b1
				MX6QDL_PAD_CSI0_DAT11__UART1_RX_DATA	0x1b0b1
			>;
		};
#endif /* CONFIG_ARMSTONEA9_UART_B */

		/* UART2 on pins 55-58 (debug port A)*/
		pinctrl_uart2_1: uart2grp-1{
			fsl,pins = <
				MX6QDL_PAD_EIM_D26__UART2_TX_DATA	0x1b0b1
				MX6QDL_PAD_EIM_D27__UART2_RX_DATA	0x1b0b1
#ifdef CONFIG_ARMSTONEA9_UART_A_RTSCTS
				MX6QDL_PAD_EIM_D28__UART2_CTS_B		0x1b0b1
				MX6QDL_PAD_EIM_D29__UART2_RTS_B		0x1b0b1
#endif /* CONFIG_ARMSTONEA9_UART_A_RTSCTS */
			>;
		};

		/* UART3 on pins 36, 38 (port C) */
		pinctrl_uart3_1: uart3grp-1{
			fsl,pins = <
				MX6QDL_PAD_EIM_D24__UART3_TX_DATA	0x1b0b1
				MX6QDL_PAD_EIM_D25__UART3_RX_DATA	0x1b0b1
			>;
		};

		/* CAN A */
		pinctrl_flexcan_a: flexcan2grp {
			fsl,pins = <
				MX6QDL_PAD_KEY_COL4__FLEXCAN2_TX	0x1b020
				MX6QDL_PAD_KEY_ROW4__FLEXCAN2_RX	0x1b020
			>;
		};

		pinctrl_usbotg: usbotggrp {
			fsl,pins = <
				/* USB_OTG_ID: low: host, open: device */
				MX6QDL_PAD_ENET_RX_ER__USB_OTG_ID 	0x1b000
				/* USB OTG host power is always on */
			>;
		};

		pinctrl_usbh1: usbh1grp {
			fsl,pins = <
				/* USB hub reset line, active low */
				MX6QDL_PAD_GPIO_17__GPIO7_IO12		0x0b0b0
				/* USB H1 host power is always on */
			>;
		};

		pinctrl_enet: enetgrp {
			fsl,pins = <
				MX6QDL_PAD_ENET_MDIO__ENET_MDIO		0x1b0b0
				MX6QDL_PAD_ENET_MDC__ENET_MDC		0x1b0b0
				MX6QDL_PAD_RGMII_TXC__RGMII_TXC		0x1b0b0
				MX6QDL_PAD_RGMII_TD0__RGMII_TD0		0x1b0b0
				MX6QDL_PAD_RGMII_TD1__RGMII_TD1		0x1b0b0
				MX6QDL_PAD_RGMII_TD2__RGMII_TD2		0x1b0b0
				MX6QDL_PAD_RGMII_TD3__RGMII_TD3		0x1b0b0
				MX6QDL_PAD_RGMII_TX_CTL__RGMII_TX_CTL	0x1b0b0
				MX6QDL_PAD_ENET_REF_CLK__ENET_TX_CLK	0x1b0b0
				MX6QDL_PAD_RGMII_RXC__RGMII_RXC		0x1b0b0
				MX6QDL_PAD_RGMII_RD0__RGMII_RD0		0x1b0b0
				MX6QDL_PAD_RGMII_RD1__RGMII_RD1		0x1b0b0
				MX6QDL_PAD_RGMII_RD2__RGMII_RD2		0x1b0b0
				MX6QDL_PAD_RGMII_RD3__RGMII_RD3		0x1b0b0
				MX6QDL_PAD_RGMII_RX_CTL__RGMII_RX_CTL	0x1b0b0
				/* Phy interrupt IO pin*/
				MX6QDL_PAD_GPIO_19__GPIO4_IO05		0x4001b0a8
				/* Phy reset IO pin*/
				MX6QDL_PAD_ENET_CRS_DV__GPIO1_IO25	0x4001b0a8
			>;
		};

#ifdef CONFIG_ARMSTONEA9_I2C_A
		/* I2C_A: Feature Connector (SKIT) */
		pinctrl_i2c3_5: i2c3grp-1 {
			fsl,pins = <
				MX6QDL_PAD_GPIO_3__I2C3_SCL		0x4001b8b1
				MX6QDL_PAD_GPIO_16__I2C3_SDA		0x4001b8b1
			>;
		};
#endif /* CONFIG_ARMSTONEA9_I2C_A */

#ifdef CONFIG_ARMSTONEA9_I2C_B
		/* I2C2 as I2C port B  (DataFlash, PMIC, RTC) */
		pinctrl_i2c2: i2c2grp {
			fsl,pins = <
				MX6QDL_PAD_KEY_COL3__I2C2_SCL		0x4001b8b1
				MX6QDL_PAD_KEY_ROW3__I2C2_SDA		0x4001b8b1
			>;
		};
#endif /* CONFIG_ARMSTONEA9_I2C_B */

#ifdef CONFIG_ARMSTONEA9_I2C_C
		/* I2C_C: additonal bus on pins 18 and 26 */
		pinctrl_i2c1: i2c1grp {
			fsl,pins = <
				MX6QDL_PAD_CSI0_DAT8__I2C1_SDA		0x4001b8b1
				MX6QDL_PAD_CSI0_DAT9__I2C1_SCL		0x4001b8b1
			>;
		};
#endif /* CONFIG_ARMSTONEA9_I2C_C */

#ifdef CONFIG_ARMSTONEA9_SGTL5000_AUDIO
		pinctrl_i2c5_gpio: i2c5_gpio_grp {
			fsl,pins = <
				MX6QDL_PAD_SD2_CMD__GPIO1_IO11		0x4001b0b0
				MX6QDL_PAD_SD2_CLK__GPIO1_IO10		0x4001b0b0
			>;
		};
#endif /* CONFIG_ARMSTONEA9_SGTL5000_AUDIO */

#if defined(CONFIG_ARMSTONEA9_SGTL5000_AUDIO) || \
	defined(CONFIG_ARMSTONEA9_HDMI_AUDIO)
		pinctrl_audmux_4: audmux-4 {
			fsl,pins = <
				MX6QDL_PAD_SD2_DAT3__AUD4_TXC		0x130b0
				MX6QDL_PAD_SD2_DAT2__AUD4_TXD		0x130b0
				MX6QDL_PAD_SD2_DAT1__AUD4_TXFS		0x130b0
				MX6QDL_PAD_SD2_DAT0__AUD4_RXD		0x130b0
			>;
		};
#endif

#ifdef CONFIG_ARMSTONEA9_HDMI
		/* HDMI interface */
		pinctrl_i2c6_gpio: i2c6_gpio_grp {
			fsl,pins = <
				MX6QDL_PAD_SD4_DAT6__GPIO2_IO14		0x70B1
				MX6QDL_PAD_SD4_DAT7__GPIO2_IO15		0x70B1
			>;
		};
#endif

		/* PWM port C - PWM1 */
		pinctrl_pwm1_1: pwm1grp {
			fsl,pins = <
				MX6QDL_PAD_SD1_DAT3__PWM1_OUT		0x110b0
			>;
		};

		/* PWM port A - PWM2 */
		pinctrl_pwm2_1: pwm2grp {
			fsl,pins = <
				MX6QDL_PAD_GPIO_1__PWM2_OUT		0x110b0
			>;
		};

		/* LVDS backlight control - PWM3 */
		pinctrl_pwm3_1: pwm3grp {
			fsl,pins = <
				MX6QDL_PAD_SD4_DAT1__PWM3_OUT		0x110b0
			>;
		};

		/* PWM port B - PWM4 */
		pinctrl_pwm4_1: pwm4grp {
			fsl,pins = <
				MX6QDL_PAD_SD4_DAT2__PWM4_OUT		0x110b0
			>;
		};

#ifdef CONFIG_ARMSTONEA9_SD_A
		pinctrl_usdhc3: usdhc3grp {
			fsl,pins = <
				MX6QDL_PAD_SD3_CMD__SD3_CMD		0x17051
				MX6QDL_PAD_SD3_CLK__SD3_CLK		0x10051
				MX6QDL_PAD_SD3_DAT0__SD3_DATA0		0x17051
				MX6QDL_PAD_SD3_DAT1__SD3_DATA1		0x17051
				MX6QDL_PAD_SD3_DAT2__SD3_DATA2		0x17051
				MX6QDL_PAD_SD3_DAT3__SD3_DATA3		0x17051
				/* RST is active low */
				MX6QDL_PAD_SD3_RST__GPIO7_IO08		0xb060
			>;
		};
#endif /* CONFIG_ARMSTONEA9_SD_A */

		pinctrl_pcie: pciegrp {
			fsl,pins = <
				/* PCIe-DIS */
				MX6QDL_PAD_DISP0_DAT21__GPIO5_IO15	0x1b0b0
				/* PCIe-RST */
				MX6QDL_PAD_DISP0_DAT23__GPIO5_IO17	0x1b0b0
				/* PCIe-WAKE */
				MX6QDL_PAD_NANDF_CS3__GPIO6_IO16	0x1b0b0
			>;
		};

		pinctrl_status_leds: ledgrp {
			fsl,pins = <
				MX6QDL_PAD_KEY_COL0__GPIO4_IO06		0x30b0
				MX6QDL_PAD_KEY_ROW0__GPIO4_IO07		0x30b0
			>;
		};
	};
};
